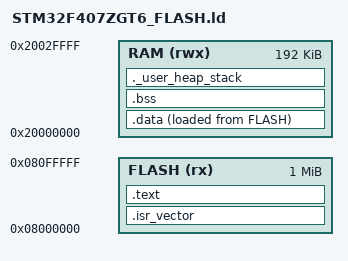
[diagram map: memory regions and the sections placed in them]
/* Linker script for STM32F407ZGT6
 * Flash: 1024 KB, RAM: 192 KB
 * Generated by rabber mcu_init v1.3.2
 */

MEMORY
{
    FLASH (rx)  : ORIGIN = 0x08000000, LENGTH = 1048576
    RAM   (rwx) : ORIGIN = 0x20000000, LENGTH = 196608
}

/* Top of stack = end of RAM */
_estack = ORIGIN(RAM) + LENGTH(RAM);

ENTRY(Reset_Handler)

SECTIONS
{
    /* ── Vector table ── */
    .isr_vector :
    {
        . = ALIGN(4);
        KEEP(*(.isr_vector))
        . = ALIGN(4);
    } > FLASH

    /* ── Program code ── */
    .text :
    {
        . = ALIGN(4);
        *(.text)
        *(.text.*)
        *(.rodata)
        *(.rodata.*)
        *(.glue_7)
        *(.glue_7t)
        . = ALIGN(4);
        _etext = .;
    } > FLASH

    /* ── Initialised data ── */
    _sidata = LOADADDR(.data);
    .data :
    {
        . = ALIGN(4);
        _sdata = .;
        *(.data)
        *(.data.*)
        . = ALIGN(4);
        _edata = .;
    } > RAM AT > FLASH

    /* ── Zero-initialised data ── */
    .bss :
    {
        . = ALIGN(4);
        _sbss = .;
        *(.bss)
        *(.bss.*)
        *(COMMON)
        . = ALIGN(4);
        _ebss = .;
    } > RAM

    /* ── Stack / heap (optional) ── */
    ._user_heap_stack :
    {
        . = ALIGN(8);
        PROVIDE(end = .);
        PROVIDE(_end = .);
        . = . + 0x400;   /* 1 KB minimum stack */
        . = ALIGN(8);
    } > RAM
}
